# ATxmega16E5 device description
Architecture: AVR8_XMEGA; Family: AVR XMEGA
Registers are 8-bit, access not given, no defined reset value unless marked. A register's access mark holds for its fields unless they carry their own. Offsets are from the block's base; [hi:lo] are bit positions; {n}, {i} and the like mark numbered series; 'fields as' and 'values as' point back to an identical list.

## AC — Analog Comparator
Instances: ACA 0x0380
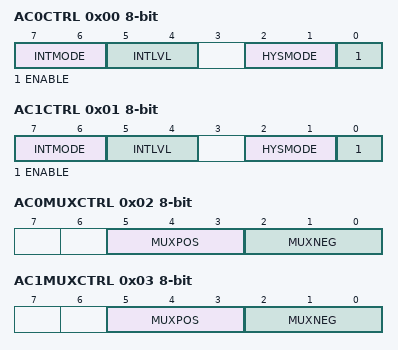
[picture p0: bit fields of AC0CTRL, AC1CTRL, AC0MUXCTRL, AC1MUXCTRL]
0x00 AC0CTRL — Analog Comparator 0 Control
  [7:6] INTMODE — Interrupt Mode
    0=BOTHEDGES (Interrupt on both edges); 2=FALLING (Interrupt on falling edge); 3=RISING (Interrupt on rising edge)
  [5:4] INTLVL — Interrupt Level
    0=OFF (Interrupt disabled); 1=LO (Low level); 2=MED (Medium level); 3=HI (High level)
  [2:1] HYSMODE — Hysteresis Mode
    0=NO (No hysteresis); 1=SMALL (Small hysteresis); 2=LARGE (Large hysteresis)
  [0] ENABLE
0x01 AC1CTRL — Analog Comparator 1 Control
  fields as AC0CTRL
0x02 AC0MUXCTRL — Analog Comparator 0 MUX Control
  [5:3] MUXPOS — MUX Positive Input
    {v}=PIN{v} (v=0..6); 7=DAC (DAC output)
  [2:0] MUXNEG — MUX Negative Input
    0=PIN0; 1=PIN1; 2=PIN3; 3=PIN5; 4=PIN7; 5=DAC (DAC output); 6=BANDGAP (Bandgap Reference); 7=SCALER (Internal voltage scaler)
0x03 AC1MUXCTRL — Analog Comparator 1 MUX Control
  fields as AC0MUXCTRL
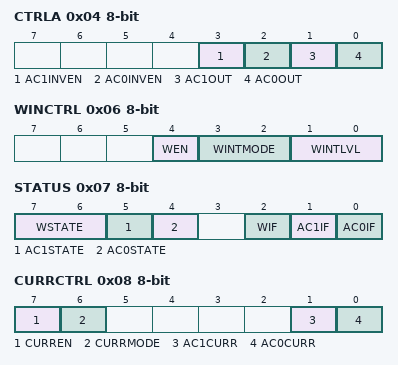
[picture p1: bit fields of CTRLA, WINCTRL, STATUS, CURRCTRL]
0x04 CTRLA — Control Register A
  [3] AC1INVEN — Analog Comparator 1 Output Invert Enable
  [2] AC0INVEN — Analog Comparator 0 Output Invert Enable
  [1] AC1OUT — Analog Comparator 1 Output Enable
  [0] AC0OUT — Analog Comparator 0 Output Enable
0x05 CTRLB — Control Register B
  [5:0] SCALEFAC — VCC Voltage Scaler Factor
0x06 WINCTRL — Window Mode Control
  [4] WEN — Window Mode Enable
  [3:2] WINTMODE — Window Interrupt Mode
    0=ABOVE (Interrupt on above window); 1=INSIDE (Interrupt on inside window); 2=BELOW (Interrupt on below window); 3=OUTSIDE (Interrupt on outside window)
  [1:0] WINTLVL — Window Interrupt Level
    0=OFF (Interrupt disabled); 1=LO (Low priority); 2=MED (Medium priority); 3=HI (High priority)
0x07 STATUS
  [7:6] WSTATE — Window Mode State
    0=ABOVE (Signal above window); 1=INSIDE (Signal inside window); 2=BELOW (Signal below window)
  [5] AC1STATE — Analog Comparator 1 State
  [4] AC0STATE — Analog Comparator 0 State
  [2] WIF — Window Mode Interrupt Flag
  [1] AC1IF — Analog Comparator 1 Interrupt Flag
  [0] AC0IF — Analog Comparator 0 Interrupt Flag
0x08 CURRCTRL — Current Source Control Register
  [7] CURREN — Current Source Enable
  [6] CURRMODE — Current Mode
  [1] AC1CURR — Analog Comparator 1 current source output
  [0] AC0CURR — Analog Comparator 0 current source output
0x09 CURRCALIB — Current Source Calibration Register
  [3:0] CALIB — Current Source Calibration

## RTC — Real-Time Counter
Instances: RTC 0x0400
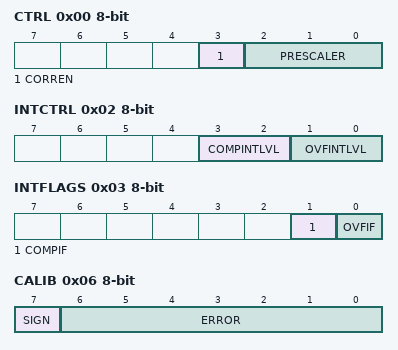
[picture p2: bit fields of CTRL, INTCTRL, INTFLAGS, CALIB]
0x00 CTRL — Control Register
  [3] CORREN — Correction Enable
  [2:0] PRESCALER — Prescaling Factor
    0=OFF (RTC Off); 1=DIV1 (RTC Clock); 2=DIV2 (RTC Clock / 2); 3=DIV8 (RTC Clock / 8); 4=DIV16 (RTC Clock / 16); 5=DIV64 (RTC Clock / 64); 6=DIV256 (RTC Clock / 256); 7=DIV1024 (RTC Clock / 1024)
0x01 STATUS
  [0] SYNCBUSY — Synchronization Busy Flag
0x02 INTCTRL — Interrupt Control Register
  [3:2] COMPINTLVL — Compare Match Interrupt Level
    0=OFF (Interrupt Disabled); 1=LO (Low Level); 2=MED (Medium Level); 3=HI (High Level)
  [1:0] OVFINTLVL — Overflow Interrupt Level
    values as COMPINTLVL
0x03 INTFLAGS — Interrupt Flags
  [1] COMPIF — Compare Match Interrupt Flag
  [0] OVFIF — Overflow Interrupt Flag
0x04 TEMP — Temporary register
0x06 CALIB — Calibration Register
  [7] SIGN — Correction Sign
  [6:0] ERROR — Error Value
0x08 CNT 16-bit — Count Register
0x0A PER 16-bit — Period Register
0x0C COMP 16-bit — Compare Register

## PORT — I/O Ports
Instances: PORTA 0x0600, PORTC 0x0640, PORTD 0x0660, PORTR 0x07E0
0x00 DIR — I/O Port Data Direction
0x01 DIRSET — I/O Port Data Direction Set
0x02 DIRCLR — I/O Port Data Direction Clear
0x03 DIRTGL — I/O Port Data Direction Toggle
0x04 OUT — I/O Port Output
0x05 OUTSET — I/O Port Output Set
0x06 OUTCLR — I/O Port Output Clear
0x07 OUTTGL — I/O Port Output Toggle
0x08 IN — I/O port Input
0x09 INTCTRL — Interrupt Control Register
  [1:0] INTLVL — Port Interrupt Level
    0=OFF (Interrupt Disabled); 1=LO (Low Level); 2=MED (Medium Level); 3=HI (High Level)
0x0A INTMASK — Port Interrupt Mask
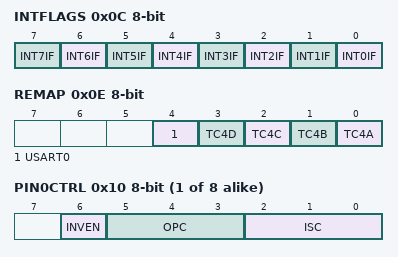
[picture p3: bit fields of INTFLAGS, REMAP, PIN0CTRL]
0x0C INTFLAGS — Interrupt Flag Register
  [n] INT{n}IF (n=0..7) — Pin {n} Interrupt Flag
0x0E REMAP — Pin Remap Register
  [4] USART0
  [3] TC4D — Timer/Counter 4 Output Compare D
  [2] TC4C — Timer/Counter 4 Output Compare C
  [1] TC4B — Timer/Counter 4 Output Compare B
  [0] TC4A — Timer/Counter 4 Output Compare A
{0x10+i} PIN{i}CTRL (i=0..7) — Pin {i} Control Register
  [6] INVEN — Inverted I/O Enable
  [5:3] OPC — Output/Pull Configuration
    0=TOTEM (Totempole); 1=BUSKEEPER (Totempole w/ Bus keeper on Input and Output); 2=PULLDOWN (Totempole w/ Pull-down on Input); 3=PULLUP (Totempole w/ Pull-up on Input); 4=WIREDOR; 5=WIREDAND; 6=WIREDORPULL (Wired OR w/ Pull-down); 7=WIREDANDPULL (Wired AND w/ Pull-up)
  [2:0] ISC — Input/Sense Configuration
    0=BOTHEDGES (Sense Both Edges); 1=RISING (Sense Rising Edge); 2=FALLING (Sense Falling Edge); 3=LEVEL (Sense Level (Transparent For Events)); 6=FORCE_ENABLE (Digital Input Buffer Forced Enable); 7=INPUT_DISABLE (Disable Digital Input Buffer)
